# M4KQ register map
File version: 0.1
Registers are 32-bit, read-write, reset 0x0 unless marked. A register's access mark holds for its fields unless they carry their own. Offsets are from the block's base; [hi:lo] are bit positions; {n}, {i} and the like mark numbered series.

## IB — Interrupt Control B Register (IB)
Base 0x40083200
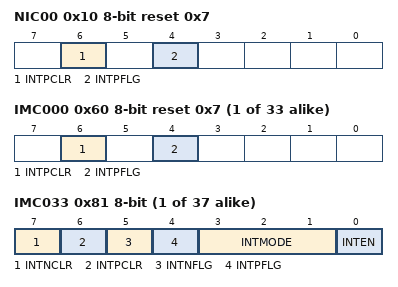
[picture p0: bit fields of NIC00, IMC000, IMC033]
0x10 NIC00 8-bit reset 0x7 — Non maskable Interrupt Control Register(B) 00
  [6] INTPCLR wo, [4] INTPFLG ro
{0x60+i} IMC{i:03} 8-bit reset 0x7 (i=0..32) — Interrupt Mode Control Register(B) {i:03}
  [6] INTPCLR wo, [4] INTPFLG ro
{0x60+i} IMC{i:03} 8-bit (i=33..69) — Interrupt Mode Control Register(B) {i:03}
  [7] INTNCLR wo, [6] INTPCLR wo, [5] INTNFLG ro, [4] INTPFLG ro, [3:1] INTMODE, [0] INTEN

## IMN — Interrupt Monitor Register (IMN)
Base 0x40083300
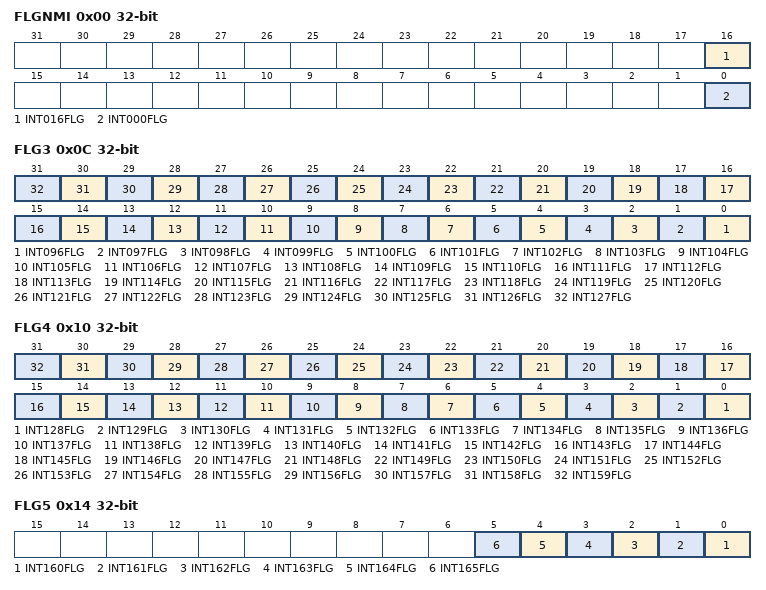
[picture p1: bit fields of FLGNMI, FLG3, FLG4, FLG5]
0x00 FLGNMI ro — NMI Interrupt Monitor Flag
  [16] INT016FLG, [0] INT000FLG
0x0C FLG3 ro — Interrupt Monitor Flag 3 (096 - 127)
  [n-96] INT{n:03}FLG (n=96..127)
0x10 FLG4 ro — Interrupt Monitor Flag 4 (128 - 159)
  [n-128] INT{n}FLG (n=128..159)
0x14 FLG5 ro — Interrupt Monitor Flag 5 (160 - 191)
  [n-160] INT{n}FLG (n=160..165)

## DNFA — Digital Noise Filter (DNF)
Base 0x400A0200
Same registers: DNFB 0x400A0300, DNFC 0x400A0800
0x00 CKCR — DNF clock Control register
  [2:0] NFCKS
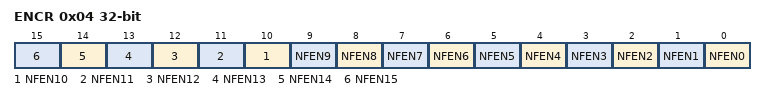
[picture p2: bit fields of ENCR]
0x04 ENCR — DNF Enable register
  [n] NFEN{n} (n=0..15)

## TSEL — Trigger Selection circuit (TSEL)
Base 0x400A0400
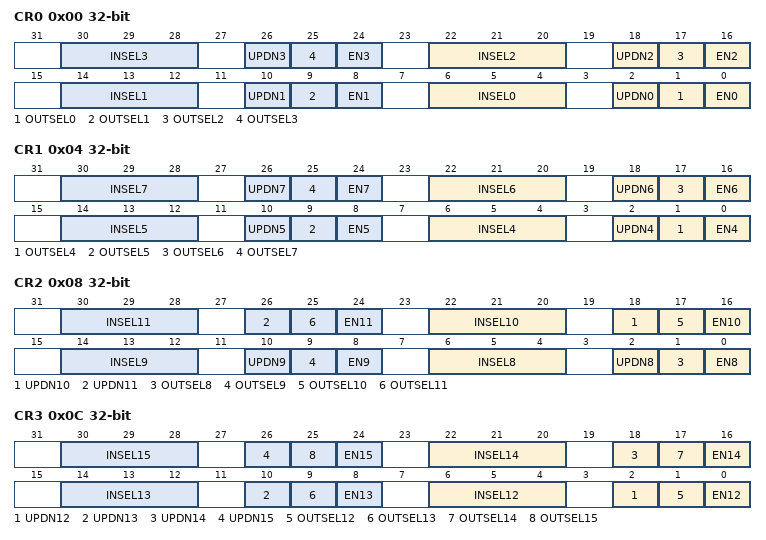
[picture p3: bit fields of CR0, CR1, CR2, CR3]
0x00 CR0 — TRGSEL Control register 0
  [8n+6:8n+4] INSEL{n} (n=0..3), [8n+2] UPDN{n} (n=0..3), [8n+1] OUTSEL{n} (n=0..3), [8n] EN{n} (n=0..3)
0x04 CR1 — TRGSEL Control register 1
  [8n-26:8n-28] INSEL{n} (n=4..7), [8n-30] UPDN{n} (n=4..7), [8n-31] OUTSEL{n} (n=4..7), [8n-32] EN{n} (n=4..7)
0x08 CR2 — TRGSEL Control register 2
  [8n-58:8n-60] INSEL{n} (n=8..11), [8n-62] UPDN{n} (n=8..11), [8n-63] OUTSEL{n} (n=8..11), [8n-64] EN{n} (n=8..11)
0x0C CR3 — TRGSEL Control register 3
  [8n-90:8n-92] INSEL{n} (n=12..15), [8n-94] UPDN{n} (n=12..15), [8n-95] OUTSEL{n} (n=12..15), [8n-96] EN{n} (n=12..15)
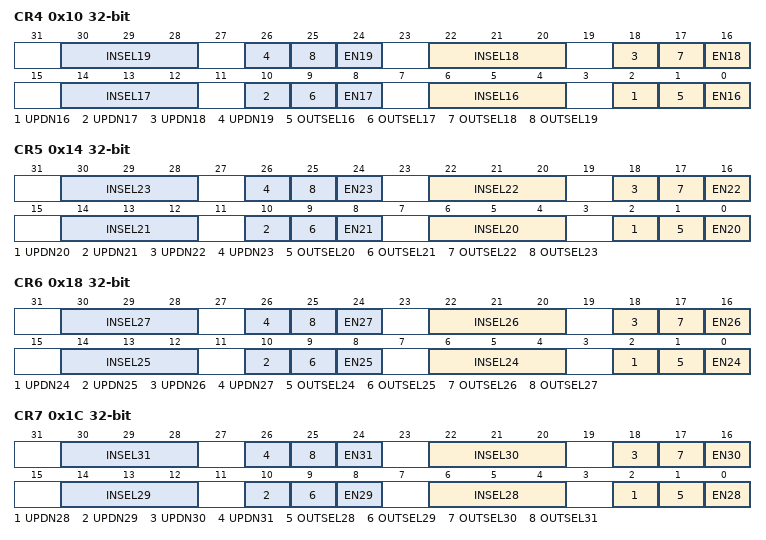
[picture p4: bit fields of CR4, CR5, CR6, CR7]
0x10 CR4 — TRGSEL Control register 4
  [8n-122:8n-124] INSEL{n} (n=16..19), [8n-126] UPDN{n} (n=16..19), [8n-127] OUTSEL{n} (n=16..19), [8n-128] EN{n} (n=16..19)
0x14 CR5 — TRGSEL Control register 5
  [8n-154:8n-156] INSEL{n} (n=20..23), [8n-158] UPDN{n} (n=20..23), [8n-159] OUTSEL{n} (n=20..23), [8n-160] EN{n} (n=20..23)
0x18 CR6 — TRGSEL Control register 6
  [8n-186:8n-188] INSEL{n} (n=24..27), [8n-190] UPDN{n} (n=24..27), [8n-191] OUTSEL{n} (n=24..27), [8n-192] EN{n} (n=24..27)
0x1C CR7 — TRGSEL Control register 7
  [8n-218:8n-220] INSEL{n} (n=28..31), [8n-222] UPDN{n} (n=28..31), [8n-223] OUTSEL{n} (n=28..31), [8n-224] EN{n} (n=28..31)
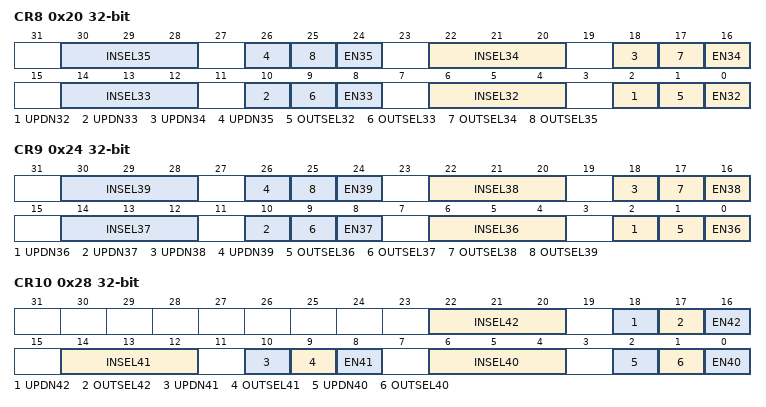
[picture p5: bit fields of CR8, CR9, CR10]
0x20 CR8 — TRGSEL Control register 8
  [8n-250:8n-252] INSEL{n} (n=32..35), [8n-254] UPDN{n} (n=32..35), [8n-255] OUTSEL{n} (n=32..35), [8n-256] EN{n} (n=32..35)
0x24 CR9 — TRGSEL Control register 9
  [8n-282:8n-284] INSEL{n} (n=36..39), [8n-286] UPDN{n} (n=36..39), [8n-287] OUTSEL{n} (n=36..39), [8n-288] EN{n} (n=36..39)
0x28 CR10 — TRGSEL Control register 10
  [22:20] INSEL42, [18] UPDN42, [17] OUTSEL42, [16] EN42, [14:12] INSEL41, [10] UPDN41, [9] OUTSEL41, [8] EN41, [6:4] INSEL40, [2] UPDN40, [1] OUTSEL40, [0] EN40

## SIWD — Watchdog Timer (SIWD)
Base 0x400A0600
0x00 PRO reset 0x1E — SIWD Protect Register
  [7:0] PROTECT
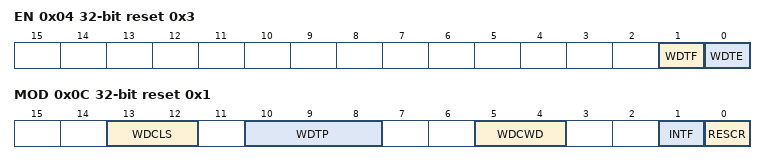
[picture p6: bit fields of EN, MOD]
0x04 EN reset 0x3 — SIWD Enable Register
  [1] WDTF ro, [0] WDTE
0x08 CR wo (reset mask 0xFFFFFF00) — SIWD Control Register
  [7:0] WDCR
0x0C MOD reset 0x1 — SIWD Mode Register
  [13:12] WDCLS, [10:8] WDTP, [5:4] WDCWD, [1] INTF, [0] RESCR
0x10 MONI ro (reset mask 0xC0000000) — SIWD Count Monitor Register
  [29:0] MONI
0x14 OSCCR — SIWD Oscillator Control Register
  [0] OSCPRO

## NBD — Non-Break Debug Interface (NBD)
Base 0x400A2000
0x00 CR0 — NBD control register 0
  [0] NBDEN
0x04 CR1 reset 0x6 — NBD control register 1
  [7:0] NBDCREN

## DMA — Direct Memory Accsess Controller (DMAC)
Base 0x400A4000
0x00 STATUS ro reset 0x101F0000 — DMA Status Register
  [0] MASTER_ENABLE
0x04 CFG wo — DMA Configuration Register
  [0] MASTER_ENABLE
0x08 CTRLBASEPTR — DMA Control Data Base Pointer Register
  [31:10] CTRL_BASE_PTR
0x0C ALTCTRLBASEPTR ro — DMA Channel Alternate Control Data Base Pointer Register
  [31:0] ALT_CTRL_BASE_PTR
0x14 CHNLSWREQUEST wo — DMA Channel Software Request Register
  [31:0] CHNL_SW_REQUEST
0x18 CHNLUSEBURSTSET — DMA Channel Useburst Set Register
  [31:0] CHNL_USEBURST_SET
0x1C CHNLUSEBURSTCLR wo — DMA Channel Useburst Clear Register
  [31:0] CHNL_USEBURST_CLR
0x20 CHNLREQMASKSET — DMA Channel Request Mask Set Register
  [31:0] CHNL_REQ_MASK_SET
0x24 CHNLREQMASKCLR wo — DMA Channel Request Mask Clear Register
  [31:0] CHNL_REQ_MASK_CLR
0x28 CHNLENABLESET — DMA Channel Enable Set Register
  [31:0] CHNL_ENABLE_SET
0x2C CHNLENABLECLR wo — DMA Channel Enable Clear Register
  [31:0] CHNL_ENABLE_CLR
0x30 CHNLPRIALTSET — DMA Channel Primary-Alternate Set Register
  [31:0] CHNL_PRI_ALT_SET
0x34 CHNLPRIALTCLR wo — DMA Channel Primary-Alternate Clear Register
  [31:0] CHNL_PRI_ALT_CLR
0x38 CHNLPRIORITYSET — DMA Channel Priority Set Register
  [31:0] CHNL_PRIORITY_SET
0x3C CHNLPRIORITYCLR wo — DMA Channel Priority Clear Register
  [31:0] CHNL_PRIORITY_CLR
0x4C ERRCLR — DMA Bus Error Clear Register
  [0] ERR_CLR
